AUTOSAR XML (schema 00048)
package /HuaweiMDC/PlatformApplication/ChassisCenterApplication/ChassisProcessStartupConfig
  startup config set ChassisStartupConfigSet
    startup config ChassisStartupConfig: scheduling-policy=SCHEDULING-POLICY-ROUND-ROBIN, scheduling-priority=12
package /HuaweiMDC/PlatformApplication/ChassisCenterApplication/Execution
  executable libchassis_a_cm
    root sw component prototype libchassis_a_cm: application-type=libchassis_a_cm
  composition sw component type chassis_a
    component diag_agent: type=diag_agent
    component chassis_a: type=libchassis_a_cm
package /HuaweiMDC/PlatformApplication/ChassisCenterApplication/SwComponent
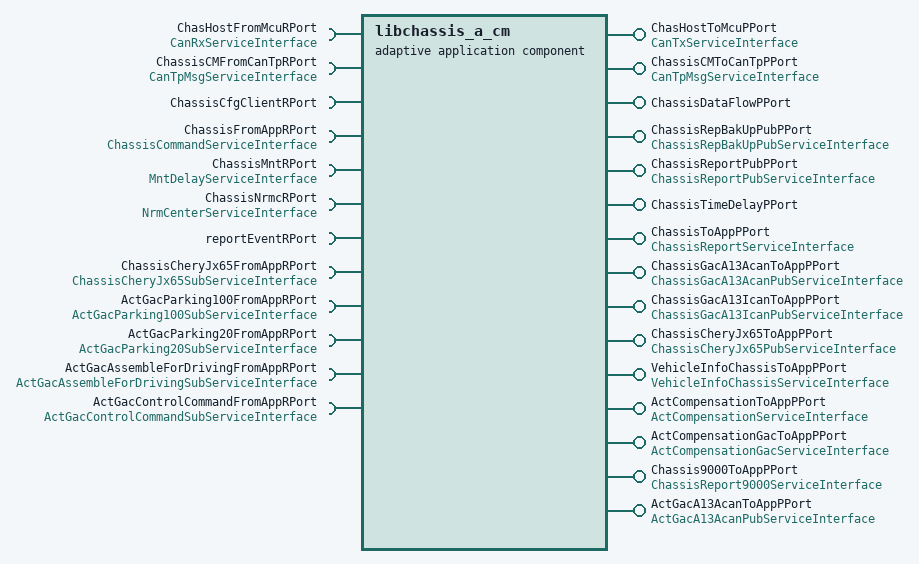
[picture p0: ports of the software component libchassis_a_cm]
  adaptive application sw component type libchassis_a_cm
    require port ChasHostFromMcuRPort: required-interface=CanRxServiceInterface
    provide port ChasHostToMcuPPort: provided-interface=CanTxServiceInterface
    require port ChassisCMFromCanTpRPort: required-interface=CanTpMsgServiceInterface
    provide port ChassisCMToCanTpPPort: provided-interface=CanTpMsgServiceInterface
    require port ChassisCfgClientRPort
    provide port ChassisDataFlowPPort
    require port ChassisFromAppRPort: required-interface=ChassisCommandServiceInterface
    require port ChassisMntRPort: required-interface=MntDelayServiceInterface
    require port ChassisNrmcRPort: required-interface=NrmCenterServiceInterface
    7 x provide port:
      ChassisRepBakUpPubPPort: provided-interface=ChassisRepBakUpPubServiceInterface
      ChassisReportPubPPort: provided-interface=ChassisReportPubServiceInterface
      ChassisTimeDelayPPort
      ChassisToAppPPort: provided-interface=ChassisReportServiceInterface
      ChassisGacA13AcanToAppPPort: provided-interface=ChassisGacA13AcanPubServiceInterface
      ChassisGacA13IcanToAppPPort: provided-interface=ChassisGacA13IcanPubServiceInterface
      ChassisCheryJx65ToAppPPort: provided-interface=ChassisCheryJx65PubServiceInterface
    require port reportEventRPort
    require port ChassisCheryJx65FromAppRPort: required-interface=ChassisCheryJx65SubServiceInterface
    5 x provide port:
      VehicleInfoChassisToAppPPort: provided-interface=VehicleInfoChassisServiceInterface
      ActCompensationToAppPPort: provided-interface=ActCompensationServiceInterface
      ActCompensationGacToAppPPort: provided-interface=ActCompensationGacServiceInterface
      Chassis9000ToAppPPort: provided-interface=ChassisReport9000ServiceInterface
      ActGacA13AcanToAppPPort: provided-interface=ActGacA13AcanPubServiceInterface
    4 x require port:
      ActGacParking100FromAppRPort: required-interface=ActGacParking100SubServiceInterface
      ActGacParking20FromAppRPort: required-interface=ActGacParking20SubServiceInterface
      ActGacAssembleForDrivingFromAppRPort: required-interface=ActGacAssembleForDrivingSubServiceInterface
      ActGacControlCommandFromAppRPort: required-interface=ActGacControlCommandSubServiceInterface
